AUTOSAR XML (schema 4-0-3)
standard types defined: Boolean, UInt16, UInt32
package /AUTOSAR_Platform/DataConstrs
  range DC_Boolean: raw 0..1
  range DC_UInt16: raw 0..65535
package /PATAC/MSM/ComponentTypes
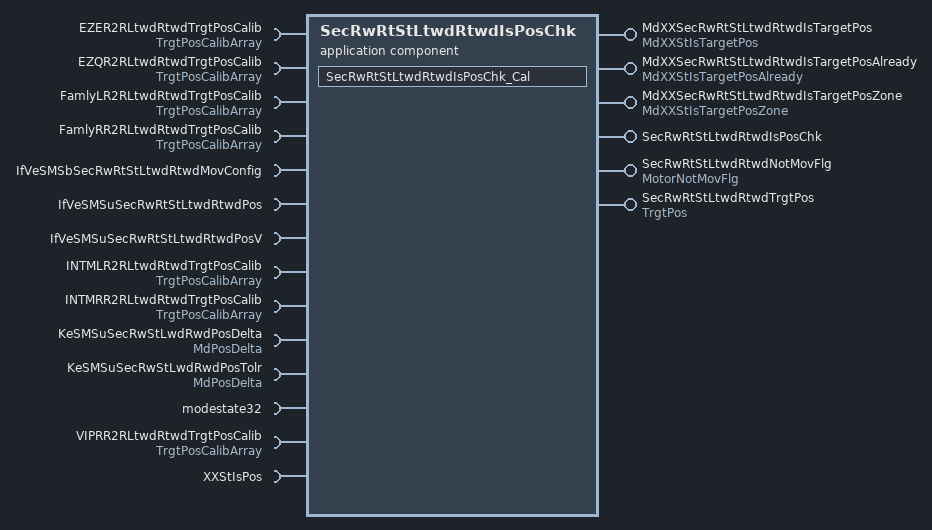
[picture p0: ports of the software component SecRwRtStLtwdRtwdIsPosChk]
  application sw component type SecRwRtStLtwdRtwdIsPosChk
    6 x provide port:
      MdXXSecRwRtStLtwdRtwdIsTargetPos: nonqueued-sender-com-spec=data-element=MdXXStIsTargetPos/Val, provided-interface=MdXXStIsTargetPos
      MdXXSecRwRtStLtwdRtwdIsTargetPosAlready: nonqueued-sender-com-spec=data-element=MdXXStIsTargetPosAlready/Val, provided-interface=MdXXStIsTargetPosAlready
      MdXXSecRwRtStLtwdRtwdIsTargetPosZone: nonqueued-sender-com-spec=data-element=MdXXStIsTargetPosZone/Val, provided-interface=MdXXStIsTargetPosZone
      SecRwRtStLtwdRtwdIsPosChk: server-com-spec{operation=Cal, queue-length=1}, provided-interface=SecRwRtStLtwdRtwdIsPosChk
      SecRwRtStLtwdRtwdNotMovFlg: nonqueued-sender-com-spec{data-element=MotorNotMovFlg/Val, init-value=0}, provided-interface=MotorNotMovFlg
      SecRwRtStLtwdRtwdTrgtPos: nonqueued-sender-com-spec{data-element=TrgtPos/Val, init-value=4095}, provided-interface=TrgtPos
    14 x require port:
      EZER2RLtwdRtwdTrgtPosCalib: nonqueued-receiver-com-spec{data-element=TrgtPosArray, filter=data-filter-type=ALWAYS, init-value=[4095, 4095, 4095]}, required-interface=TrgtPosCalibArray
      EZQR2RLtwdRtwdTrgtPosCalib: nonqueued-receiver-com-spec{data-element=TrgtPosArray, filter=data-filter-type=ALWAYS, init-value=[4095, 4095, 4095]}, required-interface=TrgtPosCalibArray
      FamlyLR2RLtwdRtwdTrgtPosCalib: nonqueued-receiver-com-spec{data-element=TrgtPosArray, filter=data-filter-type=ALWAYS, init-value=[4095, 4095, 4095]}, required-interface=TrgtPosCalibArray
      FamlyRR2RLtwdRtwdTrgtPosCalib: nonqueued-receiver-com-spec{data-element=TrgtPosArray, filter=data-filter-type=ALWAYS, init-value=[4095, 4095, 4095]}, required-interface=TrgtPosCalibArray
      IfVeSMSbSecRwRtStLtwdRtwdMovConfig: nonqueued-receiver-com-spec{data-element=IfVeSMSbSecRwRtStLtwdRtwdMovConfig/Val, filter=data-filter-type=ALWAYS, init-value=0}, required-interface=IfVeSMSbSecRwRtStLtwdRtwdMovConfig
      IfVeSMSuSecRwRtStLtwdRtwdPos: nonqueued-receiver-com-spec{data-element=IfVeSMSuSecRwRtStLtwdRtwdPos/Val, filter=data-filter-type=ALWAYS, init-value=0}, required-interface=IfVeSMSuSecRwRtStLtwdRtwdPos
      IfVeSMSuSecRwRtStLtwdRtwdPosV: nonqueued-receiver-com-spec{data-element=IfVeSMSuSecRwRtStLtwdRtwdPosV/Val, filter=data-filter-type=ALWAYS, init-value=0}, required-interface=IfVeSMSuSecRwRtStLtwdRtwdPosV
      INTMLR2RLtwdRtwdTrgtPosCalib: nonqueued-receiver-com-spec{data-element=TrgtPosArray, filter=data-filter-type=ALWAYS, init-value=[4095, 4095, 4095]}, required-interface=TrgtPosCalibArray
      INTMRR2RLtwdRtwdTrgtPosCalib: nonqueued-receiver-com-spec{data-element=TrgtPosArray, filter=data-filter-type=ALWAYS, init-value=[4095, 4095, 4095]}, required-interface=TrgtPosCalibArray
      KeSMSuSecRwStLwdRwdPosDelta: parameter-require-com-spec{init-value=150, parameter=Val}, required-interface=MdPosDelta
      KeSMSuSecRwStLwdRwdPosTolr: parameter-require-com-spec{init-value=150, parameter=Val}, required-interface=MdPosDelta
      modestate32: nonqueued-receiver-com-spec{data-element=modestate32/Val, filter=data-filter-type=ALWAYS, init-value=0}, required-interface=modestate32
      VIPRR2RLtwdRtwdTrgtPosCalib: nonqueued-receiver-com-spec{data-element=TrgtPosArray, filter=data-filter-type=ALWAYS, init-value=[4095, 4095, 4095]}, required-interface=TrgtPosCalibArray
      XXStIsPos: client-com-spec=Get, required-interface=XXStIsPos
    behavior SecRwRtStLtwdRtwdIsPosChk_InternalBehavior
      operation invoked event OIT_SecRwRtStLtwdRtwdIsPosChk_Cal_SecRwRtStLtwdRtwdIsPosChk_Cal: start-on-event=SecRwRtStLtwdRtwdIsPosChk_Cal, operation=SecRwRtStLtwdRtwdIsPosChk.Cal
      runnable SecRwRtStLtwdRtwdIsPosChk_Cal
        data-receive-point-by-arguments:
          11 x access:
            REC_EZER2RLtwdRtwdTrgtPosCalib_TrgtPosArray: accessed-variable=EZER2RLtwdRtwdTrgtPosCalib.TrgtPosArray
            REC_EZQR2RLtwdRtwdTrgtPosCalib_TrgtPosArray: accessed-variable=EZQR2RLtwdRtwdTrgtPosCalib.TrgtPosArray
            REC_FamlyLR2RLtwdRtwdTrgtPosCalib_TrgtPosArray: accessed-variable=FamlyLR2RLtwdRtwdTrgtPosCalib.TrgtPosArray
            REC_FamlyRR2RLtwdRtwdTrgtPosCalib_TrgtPosArray: accessed-variable=FamlyRR2RLtwdRtwdTrgtPosCalib.TrgtPosArray
            REC_IfVeSMSbSecRwRtStLtwdRtwdMovConfig_Val: accessed-variable=IfVeSMSbSecRwRtStLtwdRtwdMovConfig.Val
            REC_IfVeSMSuSecRwRtStLtwdRtwdPos_Val: accessed-variable=IfVeSMSuSecRwRtStLtwdRtwdPos.Val
            REC_IfVeSMSuSecRwRtStLtwdRtwdPosV_Val: accessed-variable=IfVeSMSuSecRwRtStLtwdRtwdPosV.Val
            REC_INTMLR2RLtwdRtwdTrgtPosCalib_TrgtPosArray: accessed-variable=INTMLR2RLtwdRtwdTrgtPosCalib.TrgtPosArray
            REC_INTMRR2RLtwdRtwdTrgtPosCalib_TrgtPosArray: accessed-variable=INTMRR2RLtwdRtwdTrgtPosCalib.TrgtPosArray
            REC_modestate32_Val: accessed-variable=modestate32.Val
            REC_VIPRR2RLtwdRtwdTrgtPosCalib_TrgtPosArray: accessed-variable=VIPRR2RLtwdRtwdTrgtPosCalib.TrgtPosArray
        data-send-points:
          5 x access:
            SEND_MdXXSecRwRtStLtwdRtwdIsTargetPos_Val: accessed-variable=MdXXSecRwRtStLtwdRtwdIsTargetPos.Val
            SEND_MdXXSecRwRtStLtwdRtwdIsTargetPosAlready_Val: accessed-variable=MdXXSecRwRtStLtwdRtwdIsTargetPosAlready.Val
            SEND_MdXXSecRwRtStLtwdRtwdIsTargetPosZone_Val: accessed-variable=MdXXSecRwRtStLtwdRtwdIsTargetPosZone.Val
            SEND_SecRwRtStLtwdRtwdNotMovFlg_Val: accessed-variable=SecRwRtStLtwdRtwdNotMovFlg.Val
            SEND_SecRwRtStLtwdRtwdTrgtPos_Val: accessed-variable=SecRwRtStLtwdRtwdTrgtPos.Val
        parameter access PA_KeSMSuSecRwStLwdRwdPosDelta_Val: accessed-parameter=KeSMSuSecRwStLwdRwdPosDelta.Val
        parameter access PA_KeSMSuSecRwStLwdRwdPosTolr_Val: accessed-parameter=KeSMSuSecRwStLwdRwdPosTolr.Val
        sync call SC_XXStIsPos_Get: operation=XXStIsPos.Get, timeout=0
  swc implementation SecRwRtStLtwdRtwdIsPosChk_Implementation: behavior=SecRwRtStLtwdRtwdIsPosChk_InternalBehavior
    code-descriptors:
      code Default: artifact-descriptors=autosar-engineering-object={short-label=Default, category=SWSRC}
package /PATAC/MSM/ModeAdjust/CalPortInterface
  parameter interface MdPosDelta
    parameter data prototype Val: sw-calibration-access=READ-WRITE, type=UInt16
package /PATAC/MSM/ModeAdjust/DataType
  impl type TrgtPosCalibArray: category=ARRAY, sw-calibration-access=READ-ONLY, type-emitter=RTE  # 0:pos 1:max 2:min
    element Element: array-size=3, array-size-semantics=FIXED-SIZE, implementation-data-type=UInt16, invalid-value=0
package /PATAC/MSM/ModeAdjust/Interfaces
  sender receiver interface IfVeSMSuSecRwRtStLtwdRtwdPosV: invalidation-policy{data-element=IfVeSMSuSecRwRtStLtwdRtwdPosV/Val, handle-invalid=DONT-INVALIDATE}
    data Val: type=Implementation/Boolean
package /PATAC/MSM/ModeAdjust/PortInterface
  client server interface SecRwRtStLtwdRtwdIsPosChk
    operation Cal
  client server interface XXStIsPos
    operation Get
      8 x arg, all with server-argument-impl-policy=USE-ARGUMENT-TYPE:
        PosV: type=DataTypes/Boolean, direction=IN
        Pos: type=UInt16, direction=IN
        CalibArray: type=TrgtPosCalibArray, direction=IN
        Delta: type=UInt16, direction=IN
        Tolr: type=UInt16, direction=IN
        IsPos: type=DataTypes/Boolean, direction=OUT
        IsPosZone: type=DataTypes/Boolean, direction=OUT
        IsPosAlready: type=DataTypes/Boolean, direction=OUT
  6 x sender receiver interface:
    MdXXStIsTargetPos: invalidation-policy{data-element=MdXXStIsTargetPos/Val, handle-invalid=DONT-INVALIDATE}
      data Val: type=UInt32
    MdXXStIsTargetPosAlready: invalidation-policy{data-element=MdXXStIsTargetPosAlready/Val, handle-invalid=DONT-INVALIDATE}
      data Val: type=UInt32
    MdXXStIsTargetPosZone: invalidation-policy{data-element=MdXXStIsTargetPosZone/Val, handle-invalid=DONT-INVALIDATE}
      data Val: type=UInt32
    modestate32: invalidation-policy{data-element=modestate32/Val, handle-invalid=DONT-INVALIDATE}
      data Val: type=UInt32
    MotorNotMovFlg: invalidation-policy{data-element=MotorNotMovFlg/Val, handle-invalid=DONT-INVALIDATE}
      data Val: type=Implementation/Boolean
    TrgtPosCalibArray: invalidation-policy{data-element=TrgtPosArray, handle-invalid=DONT-INVALIDATE}
      data TrgtPosArray: type=TrgtPosCalibArray  # 0:Pos 1:Max 2:Min
package /PATAC/MSM/PortInterfaces
  sender receiver interface IfVeSMSbSecRwRtStLtwdRtwdMovConfig: invalidation-policy{data-element=IfVeSMSbSecRwRtStLtwdRtwdMovConfig/Val, handle-invalid=DONT-INVALIDATE}
    data Val: type=Implementation/Boolean
  sender receiver interface IfVeSMSuSecRwRtStLtwdRtwdPos: invalidation-policy{data-element=IfVeSMSuSecRwRtStLtwdRtwdPos/Val, handle-invalid=DONT-INVALIDATE}
    data Val: type=UInt16
  sender receiver interface TrgtPos: invalidation-policy{data-element=TrgtPos/Val, handle-invalid=DONT-INVALIDATE}
    data Val: type=UInt16
